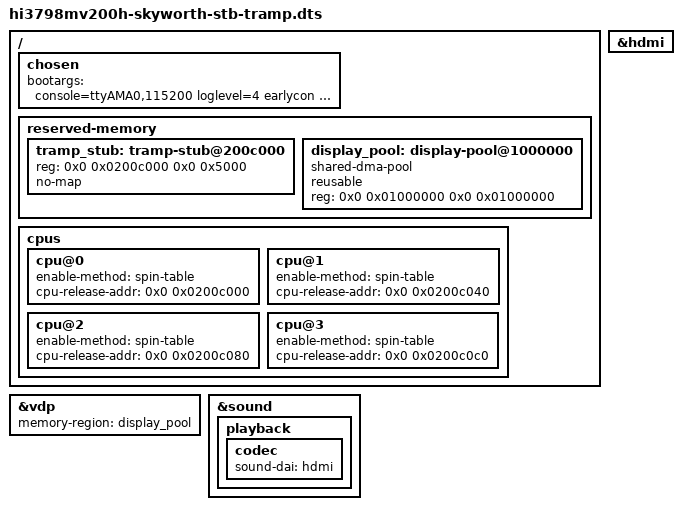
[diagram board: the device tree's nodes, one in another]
// SPDX-License-Identifier: GPL-2.0
/*
 * Trampoline variant of the Skyworth Hi3798MV200H board description.
 *
 * This build is started by the ARM32 -> AArch64 stub, not by the vendor
 * fastboot's bootm, so four things differ from the normal board file:
 *
 *   - there is no PSCI firmware under the stub, so every SMC the kernel would
 *     issue (probing PSCI, bringing up CPUs 1..3) traps instead of working.
 *     The psci node is deleted and the cpus use spin-table instead: the stub
 *     releases cores 1..3 out of reset with RVBAR pointing at its own poll loop,
 *     and each cpu-release-addr below is the slot smp_spin_table_cpu_prepare()
 *     writes __pa_symbol(secondary_holding_pen) into
 *     (arch/arm64/kernel/smp_spin_table.c:92).  Those four numbers must match
 *     REL_BASE/REL_STRIDE in the stub's tramp.inc, and verify-tramp.py decompiles
 *     this dtb to check exactly that.
 *   - the slots, stub, console lock and per-core stacks live in ordinary RAM the
 *     kernel would hand out as page frames while three cores are still fetching
 *     from it, so they get a no-map reserved-memory region.  It is a child of the
 *     dtsi's existing reserved-memory node because /memreserve/ cannot be used
 *     here: dtc requires it between /dts-v1/ and the root node, and this file
 *     #includes a .dts that already contains both.
 *   - bootargs cannot come from the fastboot env on this path, so they live in
 *     /chosen.  The initrd properties used to live here too, pointing at the
 *     archive the loader tftp'd to 0x0c000000; the rootfs is now embedded in the
 *     Image (CONFIG_INITRAMFS_SOURCE), so there is nothing for those two numbers
 *     to describe and a stale pair of them made the kernel unpack garbage.
 *   - no clk_ignore_unused: it was a bringup crutch for a provider that failed to
 *     probe (2026-10-20 board run: hi3798mv200-crg returned -22 because
 *     hisi_pll_prepare rejected bpll), which left the PL011 consumer deferred
 *     while clk_disable_unused() gated the very clock earlycon writes to.  Read
 *     from the board instead of assumed: in clk_summary every clock in use has
 *     enable_count >= 1 (clk_uart0 2/2, clk_wdg0 1/1, clk_apb 3/3, clk_ahb 2/2,
 *     clk_femacif 1/1), and the mux clk_cpu that feeds the running CPU has no
 *     .is_enabled, so clk_core_is_enabled() falls back to its enable_count and
 *     treats it as off.  What does get gated are the six with no consumer at all:
 *     I2C0/1/2, SCI0, SPI0, USB2_OTG_UTMI.
 */

#include "hi3798mv200h-skyworth-stb.dts"

/ {
	chosen {
		/* panic=15: with the SP805's restart handler as the only way back to
		 * the vendor fastboot, a panic must reach machine_restart on its own.
		 */
		/*
		 * video=HDMI-A-1:1280x720@60e is here because this bench has no
		 * sink on the HDMI output right now (TX_AON_STATE 0xf8ce4028 reads
		 * 0, while the vendor fastboot with the capture card wired reads 3),
		 * and drm_helper_probe_single_connector_modes() jumps to exit for a
		 * disconnected connector -- before drm_helper_probe_add_cmdline_mode()
		 * is ever reached.  Three shapes were measured on the board:
		 *   - "video=1280x720@60" did nothing at all: the option is looked up
		 *     per connector with video_get_options(connector->name), so a
		 *     nameless option matches no connector (round 155/2: modes=[],
		 *     "Cannot find any crtc or sizes" twice).
		 *   - the connector name is therefore required, and 'e'
		 *     (DRM_FORCE_ON, drm_modes.c:2036) is what makes
		 *     drm_probe_helper.c:589 report the connector connected without
		 *     trusting ->detect.
		 * 720p60 is exactly the 74.25 MHz the HPLL is already programmed to
		 * (clk_vo_hd read back on the board).  Bringup-only.
		 */
		bootargs = "console=ttyAMA0,115200 loglevel=4 earlycon panic=15 initcall_debug histb_vdp4.vdp_oem_copy=1 video=HDMI-A-1:1280x720@60e";
	};

	reserved-memory {
		tramp_stub: tramp-stub@200c000 {
			reg = <0x0 0x0200c000 0x0 0x5000>;
			no-map;
		};
		/*
		 * A low, reusable pool for the display surfaces (see ledger 161): the
		 * displaying OEM keeps its graphics fetch address at 0x00d25d00 while
		 * this board took its framebuffer out of the default CMA at 0x3dd00000,
		 * at the top of the 1 GiB.  "reusable" is what makes this a CMA area --
		 * without it the region was set up as a dma pool and binding it to the
		 * device failed with -EINVAL, which took the whole display probe down.
		 */
		display_pool: display-pool@1000000 {
			compatible = "shared-dma-pool";
			reusable;
			reg = <0x0 0x01000000 0x0 0x01000000>;
		};
		};


	cpus {
		cpu@0 {
			enable-method = "spin-table";
			cpu-release-addr = <0x0 0x0200c000>;
		};
		cpu@1 {
			enable-method = "spin-table";
			cpu-release-addr = <0x0 0x0200c040>;
		};
		cpu@2 {
			enable-method = "spin-table";
			cpu-release-addr = <0x0 0x0200c080>;
		};
		cpu@3 {
			enable-method = "spin-table";
			cpu-release-addr = <0x0 0x0200c0c0>;
		};
	};

	/delete-node/ psci;
};

/*
 * Board test of the display line (2026-10-22): bring up the VDP channel and
 * the transmitter downstream of it. Not for submission while the transmitter
 * still has no hot plug interrupt.
 */
&vdp {
	status = "okay";
};

&hdmi {
	status = "okay";
};

/*
 * The playback link has to move to the transmitter in the same build that
 * enables it: the board file's &hdmi node is status = "disabled", and ASoC
 * resolves the codec phandle to a device, so pointing the submitted board file
 * at &hdmi would leave the card deferred forever.  Keep the reroute in the
 * bring-up variant, next to the two enables it depends on.
 */
&sound {
	playback {
		codec {
			sound-dai = <&hdmi>;
		};
	};
};

&vdp {
	memory-region = <&display_pool>;
};
